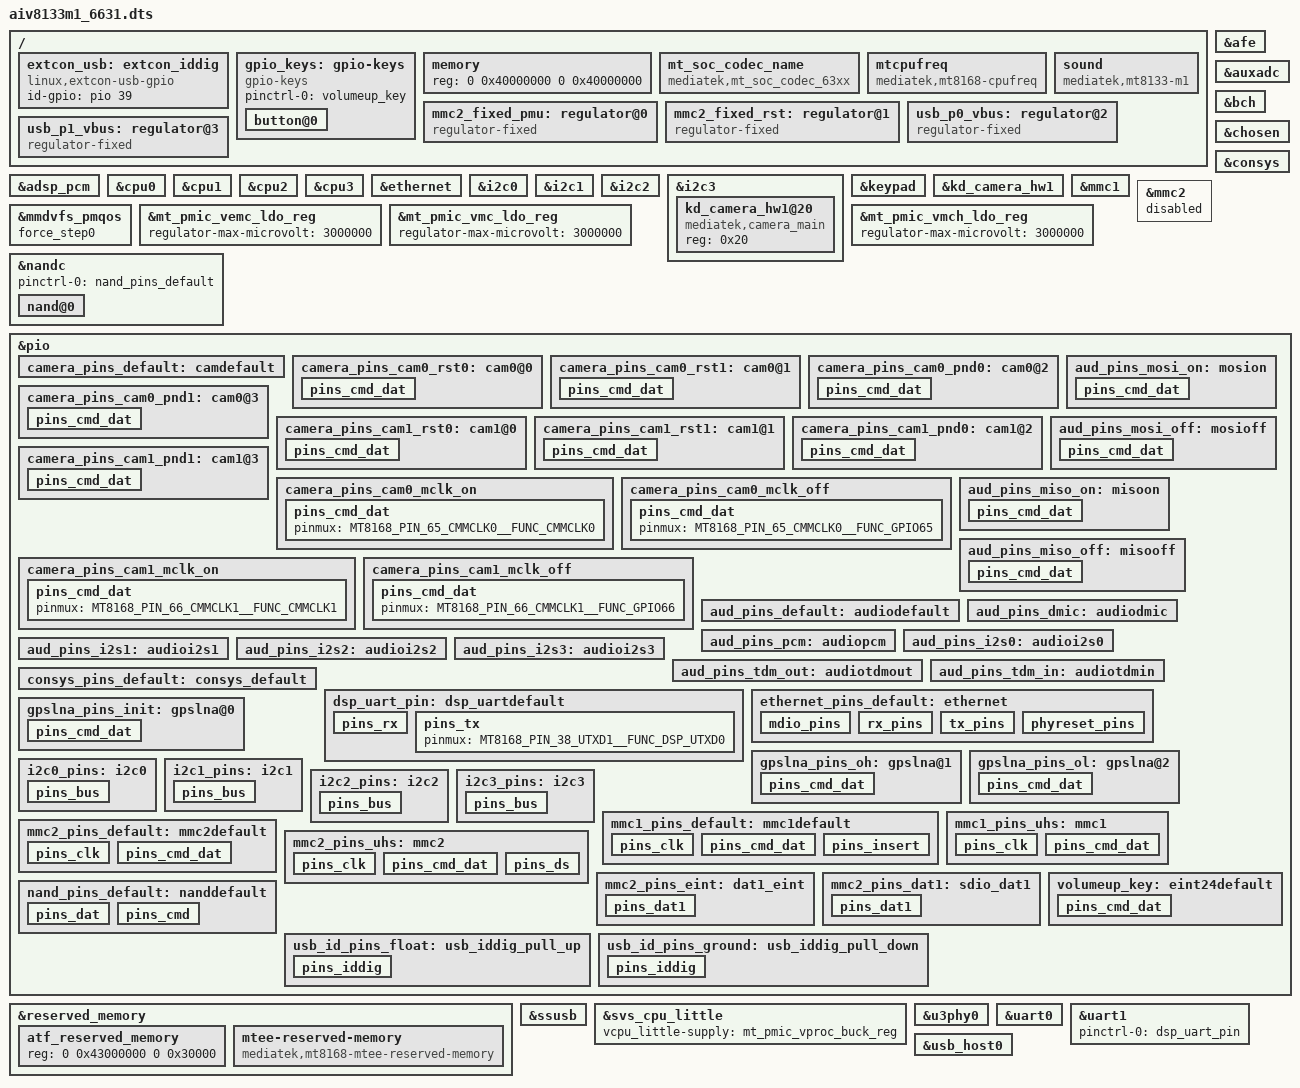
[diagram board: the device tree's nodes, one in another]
// SPDX-License-Identifier: GPL-2.0
/*
 * Copyright (c) 2019 MediaTek Inc.
 */

/dts-v1/;
#include <dt-bindings/gpio/gpio.h>
#include <dt-bindings/phy/phy.h>

#include "mt8168.dtsi"
#include "mt6357.dtsi"

/ {
	extcon_usb: extcon_iddig {
		compatible = "linux,extcon-usb-gpio";
		id-gpio = <&pio 39 GPIO_ACTIVE_HIGH>;
	};

	gpio_keys: gpio-keys {
		compatible = "gpio-keys";
		pinctrl-names = "default";
		pinctrl-0 = <&volumeup_key>;
		status = "okay";

		button@0 {
			debounce_interval = <50>;
			gpios = <&pio 24 1>;
			label = "volumeup";
			linux,input-type = <0x1>;
			linux,code = <115>;
		};
	};

	memory {
		device_type = "memory";
		reg = <0 0x40000000 0 0x40000000>;
	};

	mt_soc_codec_name: mt_soc_codec_name {
		compatible = "mediatek,mt_soc_codec_63xx";
		use_hp_depop_flow = <0>; /* select 1: use, 0: not use */
		use_ul_260k = <0>; /* select 1: use, 0: not use */
	};

	mtcpufreq {
		compatible = "mediatek,mt8168-cpufreq";
	};

	mmc2_fixed_pmu: regulator@0 {
		compatible = "regulator-fixed";
		regulator-name = "mmc2_pmu";
		regulator-min-microvolt = <3300000>;
		regulator-max-microvolt = <3300000>;
		gpio = <&pio 66 0>;
		enable-active-high;
	};

	mmc2_fixed_rst: regulator@1 {
		compatible = "regulator-fixed";
		regulator-name = "mmc2_rst";
		regulator-min-microvolt = <1800000>;
		regulator-max-microvolt = <1800000>;
		gpio = <&pio 74 0>;
		enable-active-high;
	};

	sound: sound {
		compatible = "mediatek,mt8133-m1";
		mediatek,platform = <&afe>;
		mediatek,adsp-platform = <&adsp_pcm>;
		pinctrl-names = "aud_mosi_on",
				"aud_mosi_off",
				"aud_miso_on",
				"aud_miso_off",
				"default",
				"aud_dmic",
				"aud_pcm",
				"aud_i2s0",
				"aud_i2s1",
				"aud_i2s2",
				"aud_i2s3",
				"aud_tdm_out",
				"aud_tdm_in";
		pinctrl-0 = <&aud_pins_mosi_on>;
		pinctrl-1 = <&aud_pins_mosi_off>;
		pinctrl-2 = <&aud_pins_miso_on>;
		pinctrl-3 = <&aud_pins_miso_off>;
		pinctrl-4 = <&aud_pins_default>;
		pinctrl-5 = <&aud_pins_dmic>;
		pinctrl-6 = <&aud_pins_pcm>;
		pinctrl-7 = <&aud_pins_i2s0>;
		pinctrl-8 = <&aud_pins_i2s1>;
		pinctrl-9 = <&aud_pins_i2s2>;
		pinctrl-10 = <&aud_pins_i2s3>;
		pinctrl-11 = <&aud_pins_tdm_out>;
		pinctrl-12 = <&aud_pins_tdm_in>;
		ext-amp1-gpio = <&pio 78 0>;
		status = "okay";
	};

	usb_p0_vbus: regulator@2 {
		compatible = "regulator-fixed";
		regulator-name = "vbus";
		regulator-min-microvolt = <5000000>;
		regulator-max-microvolt = <5000000>;
		gpio = <&pio 40 GPIO_ACTIVE_HIGH>;
		enable-active-high;
	};

	usb_p1_vbus: regulator@3 {
		compatible = "regulator-fixed";
		regulator-name = "vbus1";
		regulator-min-microvolt = <5000000>;
		regulator-max-microvolt = <5000000>;
		enable-active-high;
		regulator-always-on;
	};
};

&adsp_pcm {
	status = "okay";
};

&afe {
	status = "okay";
};

&auxadc {
	status = "okay";
};

&bch {
	status = "okay";
};

&chosen {
	bootargs = "console=tty0 console=ttyS0,921600n1 earlycon=uart8250,mmio32,0x11002000 vmalloc=496M skip_initramfs rootwait ro init=/sbin/init ubi.mtd=system rootfstype=ubifs root=ubi0_0";
};

&consys {
	pinctrl-names = "default", "gps_lna_state_init",
			"gps_lna_state_oh", "gps_lna_state_ol";
	pinctrl-0 = <&consys_pins_default>;
	pinctrl-1 = <&gpslna_pins_init>;
	pinctrl-2 = <&gpslna_pins_oh>;
	pinctrl-3 = <&gpslna_pins_ol>;
	status = "okay";
};

&cpu0 {
	proc-supply = <&mt_pmic_vproc_buck_reg>;
	sram-supply = <&mt_pmic_vsram_proc_ldo_reg>;
};

&cpu1 {
	proc-supply = <&mt_pmic_vproc_buck_reg>;
	sram-supply = <&mt_pmic_vsram_proc_ldo_reg>;
};

&cpu2 {
	proc-supply = <&mt_pmic_vproc_buck_reg>;
	sram-supply = <&mt_pmic_vsram_proc_ldo_reg>;
};

&cpu3 {
	proc-supply = <&mt_pmic_vproc_buck_reg>;
	sram-supply = <&mt_pmic_vsram_proc_ldo_reg>;
};

&ethernet {
	pinctrl-names = "default";
	pinctrl-0 = <&ethernet_pins_default>;
	eth-regulator-18-supply = <&mt_pmic_vsim1_ldo_reg>;
	eth-regulator-33-supply = <&mt_pmic_vcn33_wifi_ldo_reg>;
	status = "okay";
};

&i2c0 {
	pinctrl-names = "default";
	pinctrl-0 = <&i2c0_pins>;
	clock-frequency = <100000>;
	status = "okay";
};

&i2c1 {
	pinctrl-names = "default";
	pinctrl-0 = <&i2c1_pins>;
	clock-frequency = <100000>;
	status = "okay";
};

&i2c2 {
	pinctrl-names = "default";
	pinctrl-0 = <&i2c2_pins>;
	clock-frequency = <100000>;
	status = "okay";
};

&i2c3 {
	pinctrl-names = "default";
	pinctrl-0 = <&i2c3_pins>;
	clock-frequency = <100000>;
	status = "okay";

	kd_camera_hw1@20 {
		compatible = "mediatek,camera_main";
		reg = <0x20>;
	};
};

&keypad {
	mediatek,kpd-key-debounce = <1024>;
	mediatek,kpd-sw-pwrkey = <116>;
	mediatek,kpd-hw-pwrkey = <1>;
	mediatek,kpd-sw-rstkey  = <114>;
	mediatek,kpd-hw-rstkey = <3>;
	mediatek,kpd-use-extend-type = <0>;
	/*HW Keycode [0~3] -> Linux Keycode*/
	mediatek,kpd-hw-map-num = <72>;
	mediatek,kpd-hw-init-map =
			<0 0 0 0 0 0 0 0 0 0 0 0 0
			 0 0 0 0 0 0 0 0 0 0 0 0 0 0 0 0 0 0 0 0 0 0 0 0
			 0 0 0 0 0 0 0 0 0 0 0 0 0 0 0 0 0 0 0 0 0 0 0 0
			 0 0 0 0 0 0 0 0 0 0 0 >;
	mediatek,kpd-pwrkey-eint-gpio = <0>;
	mediatek,kpd-pwkey-gpio-din  = <0>;
	mediatek,kpd-hw-dl-key0 = <0>;
	mediatek,kpd-hw-dl-key1 = <3>;
	mediatek,kpd-hw-dl-key2 = <1>;
	mediatek,kpd-hw-recovery-key = <0>;
	mediatek,kpd-hw-factory-key  = <3>;
	status = "okay";
};

&kd_camera_hw1 {
	/* main cam power supply */
	vcama-supply = <&mt_pmic_vcama_ldo_reg>;         /* AVDD */
	vcamd-supply = <&mt_pmic_vcamd_ldo_reg>;         /* DVDD */
	vcamio-supply = <&mt_pmic_vcamio_ldo_reg>;       /* DOVDD */

	/* sub cam power supply */
	vcama_sub-supply = <&mt_pmic_vcama_ldo_reg>;         /* AVDD */
	vcamd_sub-supply = <&mt_pmic_vcamd_ldo_reg>;         /* DVDD */
	vcamio_sub-supply = <&mt_pmic_vcamio_ldo_reg>;       /* DOVDD */

	pinctrl-names = "default",
			"cam0_rst0", "cam0_rst1", "cam0_pnd0", "cam0_pnd1",
			"cam1_rst0", "cam1_rst1", "cam1_pnd0", "cam1_pnd1",
			"cam0_mclk_on", "cam0_mclk_off",
			"cam1_mclk_on", "cam1_mclk_off";

	pinctrl-0 = <&camera_pins_default>;
	pinctrl-1 = <&camera_pins_cam0_rst0>;
	pinctrl-2 = <&camera_pins_cam0_rst1>;
	pinctrl-3 = <&camera_pins_cam0_pnd0>;
	pinctrl-4 = <&camera_pins_cam0_pnd1>;
	pinctrl-5 = <&camera_pins_cam1_rst0>;
	pinctrl-6 = <&camera_pins_cam1_rst1>;
	pinctrl-7 = <&camera_pins_cam1_pnd0>;
	pinctrl-8 = <&camera_pins_cam1_pnd1>;
	pinctrl-9 = <&camera_pins_cam0_mclk_on>;
	pinctrl-10 = <&camera_pins_cam0_mclk_off>;
	pinctrl-11 = <&camera_pins_cam1_mclk_on>;
	pinctrl-12 = <&camera_pins_cam1_mclk_off>;

	status = "okay";
};

&mmc1 {
	pinctrl-names = "default", "state_uhs";
	pinctrl-0 = <&mmc1_pins_default>;
	pinctrl-1 = <&mmc1_pins_uhs>;
	bus-width = <4>;
	max-frequency = <200000000>;
	cap-sd-highspeed;
	sd-uhs-sdr50;
	sd-uhs-sdr104;
	cd-gpios = <&pio 75 GPIO_ACTIVE_LOW>;
	vmmc-supply = <&mt_pmic_vmch_ldo_reg>;
	vqmmc-supply = <&mt_pmic_vmc_ldo_reg>;
	no-mmc;
	no-sdio;
	status = "okay";
};

&mmc2 {
	status = "disabled";
	pinctrl-names = "default", "state_uhs", "state_eint", "state_dat1";
	pinctrl-0 = <&mmc2_pins_default>;
	pinctrl-1 = <&mmc2_pins_uhs>;
	pinctrl-2 = <&mmc2_pins_eint>;
	pinctrl-3 = <&mmc2_pins_dat1>;
	eint-gpios = <&pio 83 0>;
	bus-width = <4>;
	max-frequency = <200000000>;
	cap-sd-highspeed;
	sd-uhs-sdr104;
	sd-uhs-sdr50;
	sd-uhs-sdr25;
	keep-power-in-suspend;
	enable-sdio-wakeup;
	cap-sdio-irq;
	no-mmc;
	no-sd;
	non-removable;
	vmmc-supply = <&mmc2_fixed_pmu>;
	vqmmc-supply = <&mmc2_fixed_rst>;
	assigned-clocks = <&topckgen CLK_TOP_MSDC50_2_SEL>;
	ssigned-clock-parents = <&topckgen CLK_TOP_MSDCPLL>;
};

&mmdvfs_pmqos {
	force_step0;
};

&mt_pmic_vemc_ldo_reg {
	regulator-max-microvolt = <3000000>;
};

&mt_pmic_vmc_ldo_reg {
	regulator-max-microvolt = <3000000>;
};

&mt_pmic_vmch_ldo_reg {
	regulator-max-microvolt = <3000000>;
};

&nandc {
	pinctrl-names = "default";
	pinctrl-0 = <&nand_pins_default>;
	status = "okay";
	nand@0 {
		reg = <0>;
		nand-on-flash-bbt;
		nand-ecc-mode = "hw";
	};
};

&pio {
	pinctrl-names = "default";

	camera_pins_default: camdefault {
	};

	camera_pins_cam0_rst0: cam0@0 {
		pins_cmd_dat {
			pinmux = <MT8168_PIN_68_CMDAT0__FUNC_GPIO68>;
			slew-rate = <1>; /*direction 0:in, 1:out*/
			output-low;
		};
	};

	camera_pins_cam0_rst1: cam0@1 {
		pins_cmd_dat {
			pinmux = <MT8168_PIN_68_CMDAT0__FUNC_GPIO68>;
			slew-rate = <1>;
			output-high;
		};
	};

	camera_pins_cam0_pnd0: cam0@2 {
		pins_cmd_dat {
			pinmux = <MT8168_PIN_69_CMDAT1__FUNC_GPIO69>;
			slew-rate = <1>;
			output-low;
		};
	};

	camera_pins_cam0_pnd1: cam0@3 {
		pins_cmd_dat {
			pinmux = <MT8168_PIN_69_CMDAT1__FUNC_GPIO69>;
			slew-rate = <1>;
			output-high;
		};
	};

	camera_pins_cam1_rst0: cam1@0 {
		pins_cmd_dat {
			pinmux = <MT8168_PIN_28_SPI_MI__FUNC_GPIO28>;
			slew-rate = <1>; /*direction 0:in, 1:out*/
			output-low;
		};
	};

	camera_pins_cam1_rst1: cam1@1 {
		pins_cmd_dat {
			pinmux = <MT8168_PIN_28_SPI_MI__FUNC_GPIO28>;
			slew-rate = <1>;
			output-high;
		};
	};

	camera_pins_cam1_pnd0: cam1@2 {
		pins_cmd_dat {
			pinmux = <MT8168_PIN_27_SPI_CK__FUNC_GPIO27>;
			slew-rate = <1>;
			output-low;
		};
	};

	camera_pins_cam1_pnd1: cam1@3 {
		pins_cmd_dat {
			pinmux = <MT8168_PIN_27_SPI_CK__FUNC_GPIO27>;
			slew-rate = <1>;
			output-high;
		};
	};

	camera_pins_cam0_mclk_on: camera_pins_cam0_mclk_on {
		pins_cmd_dat {
			pinmux = <MT8168_PIN_65_CMMCLK0__FUNC_CMMCLK0>;
		};
	};

	camera_pins_cam0_mclk_off: camera_pins_cam0_mclk_off {
		pins_cmd_dat {
			pinmux = <MT8168_PIN_65_CMMCLK0__FUNC_GPIO65>;
		};
	};

	camera_pins_cam1_mclk_on: camera_pins_cam1_mclk_on {
		pins_cmd_dat {
			pinmux = <MT8168_PIN_66_CMMCLK1__FUNC_CMMCLK1>;
		};
	};

	camera_pins_cam1_mclk_off: camera_pins_cam1_mclk_off {
		pins_cmd_dat {
			pinmux = <MT8168_PIN_66_CMMCLK1__FUNC_GPIO66>;
		};
	};

	aud_pins_mosi_on: mosion {
		pins_cmd_dat {
		pinmux = <MT8168_PIN_49_AUD_CLK_MOSI__FUNC_AUD_CLK_MOSI>,
			 <MT8168_PIN_50_AUD_SYNC_MOSI__FUNC_AUD_SYNC_MOSI>,
			 <MT8168_PIN_51_AUD_DAT_MOSI0__FUNC_AUD_DAT_MOSI0>,
			 <MT8168_PIN_52_AUD_DAT_MOSI1__FUNC_AUD_DAT_MOSI1>;
		drive-strength = <MTK_DRIVE_6mA>;
		};
	};

	aud_pins_mosi_off: mosioff {
		pins_cmd_dat {
		pinmux = <MT8168_PIN_49_AUD_CLK_MOSI__FUNC_GPIO49>,
			 <MT8168_PIN_50_AUD_SYNC_MOSI__FUNC_GPIO50>,
			 <MT8168_PIN_51_AUD_DAT_MOSI0__FUNC_GPIO51>,
			 <MT8168_PIN_52_AUD_DAT_MOSI1__FUNC_GPIO52>;
		};
	};

	aud_pins_miso_on: misoon {
		pins_cmd_dat {
		pinmux = <MT8168_PIN_53_AUD_CLK_MISO__FUNC_AUD_CLK_MISO>,
			 <MT8168_PIN_54_AUD_SYNC_MISO__FUNC_AUD_SYNC_MISO>,
			 <MT8168_PIN_55_AUD_DAT_MISO0__FUNC_AUD_DAT_MISO0>,
			 <MT8168_PIN_56_AUD_DAT_MISO1__FUNC_AUD_DAT_MISO1>;
		drive-strength = <MTK_DRIVE_6mA>;
		};
	};

	aud_pins_miso_off: misooff {
		pins_cmd_dat {
		pinmux = <MT8168_PIN_53_AUD_CLK_MISO__FUNC_GPIO53>,
			 <MT8168_PIN_54_AUD_SYNC_MISO__FUNC_GPIO54>,
			 <MT8168_PIN_55_AUD_DAT_MISO0__FUNC_GPIO55>,
			 <MT8168_PIN_56_AUD_DAT_MISO1__FUNC_GPIO56>;
		};
	};

	aud_pins_default: audiodefault {
	};

	aud_pins_dmic: audiodmic {
	};

	aud_pins_pcm: audiopcm {
	};

	aud_pins_i2s0: audioi2s0 {
	};

	aud_pins_i2s1: audioi2s1 {
	};

	aud_pins_i2s2: audioi2s2 {
	};

	aud_pins_i2s3: audioi2s3 {
	};

	aud_pins_tdm_out: audiotdmout {
	};

	aud_pins_tdm_in: audiotdmin {
	};

	consys_pins_default: consys_default {
	};

	dsp_uart_pin: dsp_uartdefault {
		pins_rx {
			pinmux = <MT8168_PIN_37_URXD1__FUNC_DSP_URXD0>;
			input-enable;
			bias-pull-up;
		};
		pins_tx {
			pinmux = <MT8168_PIN_38_UTXD1__FUNC_DSP_UTXD0>;
		};
	};

	ethernet_pins_default: ethernet {
		mdio_pins {
			pinmux = <MT8168_PIN_14_GPIO14__FUNC_EXT_MDIO>,
				 <MT8168_PIN_15_GPIO15__FUNC_EXT_MDC>;
		};
		rx_pins {
			pinmux = <MT8168_PIN_6_GPIO6__FUNC_EXT_RXC>,
				 <MT8168_PIN_8_GPIO8__FUNC_EXT_RXD0>,
				 <MT8168_PIN_9_GPIO9__FUNC_EXT_RXD1>,
				 <MT8168_PIN_10_GPIO10__FUNC_EXT_RXD2>,
				 <MT8168_PIN_11_GPIO11__FUNC_EXT_RXD3>,
				 <MT8168_PIN_7_GPIO7__FUNC_EXT_RXDV>,
				 <MT8168_PIN_5_GPIO5__FUNC_EXT_RXER>,
				 <MT8168_PIN_13_GPIO13__FUNC_EXT_COL>;
		};
		tx_pins {
			pinmux = <MT8168_PIN_4_GPIO4__FUNC_EXT_TXC>,
				 <MT8168_PIN_0_GPIO0__FUNC_EXT_TXD0>,
				 <MT8168_PIN_1_GPIO1__FUNC_EXT_TXD1>,
				 <MT8168_PIN_2_GPIO2__FUNC_EXT_TXD2>,
				 <MT8168_PIN_3_GPIO3__FUNC_EXT_TXD3>,
				 <MT8168_PIN_12_GPIO12__FUNC_EXT_TXEN>;
		};
		phyreset_pins {
			pinmux = <MT8168_PIN_22_KPROW0__FUNC_GPIO22>;
			output-high;
		};
	};

	gpslna_pins_init: gpslna@0 {
		pins_cmd_dat {
			pinmux = <MT8168_PIN_70_CMDAT2__FUNC_GPIO70>;
			slew-rate = <0>;
			bias-disable;
			output-low;
		};
	};

	gpslna_pins_oh: gpslna@1 {
		pins_cmd_dat {
			pinmux = <MT8168_PIN_70_CMDAT2__FUNC_GPIO70>;
			slew-rate = <1>;
			output-high;
		};
	};

	gpslna_pins_ol: gpslna@2 {
		pins_cmd_dat {
			pinmux = <MT8168_PIN_70_CMDAT2__FUNC_GPIO70>;
			slew-rate = <1>;
			output-low;
		};
	};

	i2c0_pins: i2c0 {
		pins_bus {
			pinmux = <MT8168_PIN_57_SDA0__FUNC_SDA0_0>,
				 <MT8168_PIN_58_SCL0__FUNC_SCL0_0>;
			bias-pull-up = <MTK_RSEL_SET_R1R0_11>;
		};
	};

	i2c1_pins: i2c1 {
		pins_bus {
			pinmux = <MT8168_PIN_59_SDA1__FUNC_SDA1_0>,
				 <MT8168_PIN_60_SCL1__FUNC_SCL1_0>;
			bias-pull-up = <MTK_RSEL_SET_R1R0_11>;
		};
	};

	i2c2_pins: i2c2 {
		pins_bus {
			pinmux = <MT8168_PIN_61_SDA2__FUNC_SDA2_0>,
				 <MT8168_PIN_62_SCL2__FUNC_SCL2_0>;
			bias-pull-up = <MTK_RSEL_SET_R1R0_11>;
		};
	};

	i2c3_pins: i2c3 {
		pins_bus {
			pinmux = <MT8168_PIN_63_SDA3__FUNC_SDA3_0>,
				 <MT8168_PIN_64_SCL3__FUNC_SCL3_0>;
			bias-pull-up = <MTK_RSEL_SET_R1R0_11>;
		};
	};

	mmc1_pins_default: mmc1default {
		pins_clk {
			pinmux = <MT8168_PIN_88_MSDC1_CLK__FUNC_MSDC1_CLK>;
			drive-strength = <MTK_DRIVE_4mA>;
			bias-pull-down = <MTK_PUPD_SET_R1R0_10>;
		};

		pins_cmd_dat {
			pinmux = <MT8168_PIN_89_MSDC1_DAT0__FUNC_MSDC1_DAT0>,
				 <MT8168_PIN_90_MSDC1_DAT1__FUNC_MSDC1_DAT1>,
				 <MT8168_PIN_91_MSDC1_DAT2__FUNC_MSDC1_DAT2>,
				 <MT8168_PIN_92_MSDC1_DAT3__FUNC_MSDC1_DAT3>,
				 <MT8168_PIN_87_MSDC1_CMD__FUNC_MSDC1_CMD>;
			input-enable;
			drive-strength = <MTK_DRIVE_4mA>;
			bias-pull-up = <MTK_PUPD_SET_R1R0_01>;
		};

		pins_insert {
			pinmux = <MT8168_PIN_75_CMDAT7__FUNC_GPIO75>;
			bias-pull-up;
		};
	};

	mmc1_pins_uhs: mmc1 {
		pins_clk {
			pinmux = <MT8168_PIN_88_MSDC1_CLK__FUNC_MSDC1_CLK>;
			drive-strength = <MTK_DRIVE_6mA>;
			bias-pull-down = <MTK_PUPD_SET_R1R0_10>;
		};

		pins_cmd_dat {
			pinmux = <MT8168_PIN_89_MSDC1_DAT0__FUNC_MSDC1_DAT0>,
				 <MT8168_PIN_90_MSDC1_DAT1__FUNC_MSDC1_DAT1>,
				 <MT8168_PIN_91_MSDC1_DAT2__FUNC_MSDC1_DAT2>,
				 <MT8168_PIN_92_MSDC1_DAT3__FUNC_MSDC1_DAT3>,
				 <MT8168_PIN_87_MSDC1_CMD__FUNC_MSDC1_CMD>;
			input-enable;
			drive-strength = <MTK_DRIVE_6mA>;
			bias-pull-up = <MTK_PUPD_SET_R1R0_01>;
		};
	};

	mmc2_pins_default: mmc2default {
		pins_clk {
			pinmux = <MT8168_PIN_81_MSDC2_CLK__FUNC_MSDC2_CLK>;
			drive-strength = <MTK_DRIVE_4mA>;
			bias-pull-down = <MTK_PUPD_SET_R1R0_10>;
		};

		pins_cmd_dat {
			pinmux = <MT8168_PIN_82_MSDC2_DAT0__FUNC_MSDC2_DAT0>,
				 <MT8168_PIN_83_MSDC2_DAT1__FUNC_MSDC2_DAT1>,
				 <MT8168_PIN_84_MSDC2_DAT2__FUNC_MSDC2_DAT2>,
				 <MT8168_PIN_85_MSDC2_DAT3__FUNC_MSDC2_DAT3>,
				 <MT8168_PIN_80_MSDC2_CMD__FUNC_MSDC2_CMD>;
			input-enable;
			drive-strength = <MTK_DRIVE_4mA>;
			bias-pull-up = <MTK_PUPD_SET_R1R0_01>;
		};
	};

	mmc2_pins_uhs: mmc2 {
		pins_clk {
			pinmux = <MT8168_PIN_81_MSDC2_CLK__FUNC_MSDC2_CLK>;
			drive-strength = <MTK_DRIVE_8mA>;
			bias-pull-down = <MTK_PUPD_SET_R1R0_10>;
		};

		pins_cmd_dat {
			pinmux = <MT8168_PIN_82_MSDC2_DAT0__FUNC_MSDC2_DAT0>,
				 <MT8168_PIN_83_MSDC2_DAT1__FUNC_MSDC2_DAT1>,
				 <MT8168_PIN_84_MSDC2_DAT2__FUNC_MSDC2_DAT2>,
				 <MT8168_PIN_85_MSDC2_DAT3__FUNC_MSDC2_DAT3>,
				 <MT8168_PIN_80_MSDC2_CMD__FUNC_MSDC2_CMD>;
			input-enable;
			drive-strength = <MTK_DRIVE_8mA>;
			bias-pull-up = <MTK_PUPD_SET_R1R0_01>;
		};

		pins_ds {
			pinmux = <MT8168_PIN_86_MSDC2_DSL__FUNC_MSDC2_DSL>;
			drive-strength = <MTK_DRIVE_8mA>;
			bias-pull-down = <MTK_PUPD_SET_R1R0_10>;
		};
	};

	mmc2_pins_eint: dat1_eint {
		pins_dat1 {
			pinmux = <MT8168_PIN_83_MSDC2_DAT1__FUNC_GPIO83>;
			output-high;
		};
	};

	mmc2_pins_dat1: sdio_dat1 {
		pins_dat1 {
			pinmux = <MT8168_PIN_83_MSDC2_DAT1__FUNC_MSDC2_DAT1>;
			input-enable;
			drive-strength = <MTK_DRIVE_8mA>;
			bias-pull-up = <MTK_PUPD_SET_R1R0_01>;
		};
	};

	nand_pins_default: nanddefault {
		pins_dat {
			pinmux = <MT8168_PIN_93_MSDC0_DAT7__FUNC_NLD7>,
				 <MT8168_PIN_94_MSDC0_DAT6__FUNC_NLD6>,
				 <MT8168_PIN_101_MSDC0_DAT2__FUNC_NLD5>,
				 <MT8168_PIN_95_MSDC0_DAT5__FUNC_NLD4>,
				 <MT8168_PIN_96_MSDC0_DAT4__FUNC_NLD3>,
				 <MT8168_PIN_103_MSDC0_DAT0__FUNC_NLD2>,
				 <MT8168_PIN_100_MSDC0_DAT3__FUNC_NLD1>,
				 <MT8168_PIN_97_MSDC0_RSTB__FUNC_NLD0>,
				 <MT8168_PIN_102_MSDC0_DAT1__FUNC_NDQS>;
			input-enable;
			bias-pull-up;
		};

		pins_cmd {
			pinmux = <MT8168_PIN_109_NRNB__FUNC_NRNB>,
				 <MT8168_PIN_98_MSDC0_CMD__FUNC_NALE>,
				 <MT8168_PIN_105_NCLE__FUNC_NCLE>,
				 <MT8168_PIN_108_NREB__FUNC_NREB>,
				 <MT8168_PIN_99_MSDC0_CLK__FUNC_NWEB>,
				 <MT8168_PIN_106_NCEB1__FUNC_NCEB1>,
				 <MT8168_PIN_107_NCEB0__FUNC_NCEB0>;
			bias-pull-up;
		};
	};

	usb_id_pins_float: usb_iddig_pull_up {
		pins_iddig {
			pinmux = <MT8168_PIN_39_URXD2__FUNC_IDDIG>;
			bias-pull-up;
		};
	};

	usb_id_pins_ground: usb_iddig_pull_down {
		pins_iddig {
			pinmux = <MT8168_PIN_39_URXD2__FUNC_IDDIG>;
			bias-pull-down;
		};
	};

	volumeup_key: eint24default {
		pins_cmd_dat {
			pinmux = <MT8168_PIN_24_KPCOL0__FUNC_GPIO24>;
			slew-rate = <0>;
			bias-pull-up = <MTK_PUPD_SET_R1R0_01>;
			input-enable;
		};
	};
};

&reserved_memory {
	#address-cells = <2>;
	#size-cells = <2>;

	atf_reserved_memory {
		reg = <0 0x43000000 0 0x30000>;
	};


	mtee-reserved-memory {
		compatible = "mediatek,mt8168-mtee-reserved-memory";
		no-map;
		reg = <0 0x7fe00000 0 0x200000>;
	};
};

&ssusb {
	phys = <&u2port0 PHY_TYPE_USB2>,
	       <&u2port1 PHY_TYPE_USB2>;
	vusb33-supply = <&mt_pmic_vusb33_ldo_reg>;
	vbus-supply = <&usb_p0_vbus>;
	extcon = <&extcon_usb>;
	dr_mode = "peripheral";
	pinctrl-names = "default", "id_float", "id_ground";
	pinctrl-0 = <&usb_id_pins_float>;
	pinctrl-1 = <&usb_id_pins_float>;
	pinctrl-2 = <&usb_id_pins_ground>;
	status="okay";
};

&svs_cpu_little {
	vcpu_little-supply = <&mt_pmic_vproc_buck_reg>;
};

&u3phy0 {
	status="okay";
};

&uart0 {
	status="okay";
};

&uart1 {
	pinctrl-names = "default";
	pinctrl-0 = <&dsp_uart_pin>;
	status="okay";
};

&usb_host0 {
	vusb33-supply = <&mt_pmic_vusb33_ldo_reg>;
	vbus-supply = <&usb_p1_vbus>;
	status = "okay";
};
